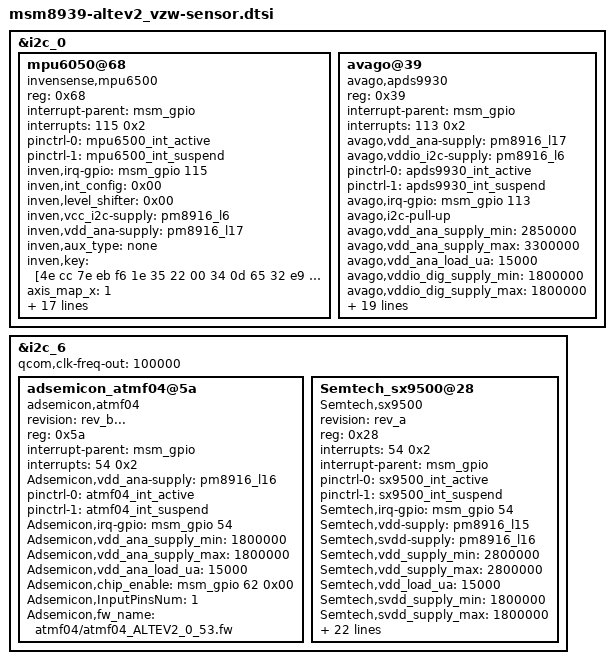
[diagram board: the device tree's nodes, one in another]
/* Copyright (c) 2012, Code Aurora Forum. All rights reserved.
 *
 * This program is free software; you can redistribute it and/or modify
 * it under the terms of the GNU General Public License version 2 and
 * only version 2 as published by the Free Software Foundation.
 *
 * This program is distributed in the hope that it will be useful,
 * but WITHOUT ANY WARRANTY; without even the implied warranty of
 * MERCHANTABILITY or FITNESS FOR A PARTICULAR PURPOSE.  See the
 * GNU General Public License for more details.
 */

&i2c_0{
	/* BLSP1 QUP2, LGP-s19 sensor devices */
	/* LGE_CHANGE_S
	* Comment : add to enable Invensense MPU6515 6-axis sensor
	* 2014-08-05, chaesun.leem@lge.com
	*/
	mpu6050@68{
		compatible = "invensense,mpu6500";
		status = "ok";
		reg = <0x68>;
		interrupt-parent = <&msm_gpio>;
		interrupts = <115 0x2>;
		pinctrl-names = "default", "sleep";
		pinctrl-0 = <&mpu6500_int_active>;
		pinctrl-1 = <&mpu6500_int_suspend>;
		inven,irq-gpio = <&msm_gpio 115 0x00>;		/*	SMS_GPIO_BASE(112) + 3	*/
		inven,int_config = <0x00>;
		inven,level_shifter = <0x00>;
		inven,vcc_i2c-supply = <&pm8916_l6>;
		inven,vdd_ana-supply = <&pm8916_l17>;
		/* inven,secondary_type = "none"; */
		inven,aux_type = "none";
		inven,key = [4e cc 7e eb f6 1e 35 22 00 34 0d 65 32 e9 94 89];
		axis_map_x = <1>;
		axis_map_y = <0>;
		axis_map_z = <2>;
		negate_x = <1>;
		negate_y = <1>;
		negate_z = <1>;

		poll_interval = <200>;
		min_interval = <5>;
		inven,secondary_reg = <0x0c>;
		inven,secondary_reest = <&msm_gpio 69 0x00>;
		/* If no compass sensor,
		 * replace "compass" with "none"
		 */
		inven,secondary_type = "compass";
		inven,secondary_name = "ak09911";
		inven,secondary_axis_map_x = <1>;
		inven,secondary_axis_map_y = <0>;
		inven,secondary_axis_map_z = <2>;
		inven,secondary_negate_x = <1>;
		inven,secondary_negate_y = <1>;
		inven,secondary_negate_z = <1>;
	};
	avago@39{
		compatible = "avago,apds9930";
		status ="ok";
		reg = <0x39>;
		interrupt-parent = <&msm_gpio>;
		interrupts = <113 0x2>;
		avago,vdd_ana-supply = <&pm8916_l17>;
		avago,vddio_i2c-supply = <&pm8916_l6>;
		pinctrl-names = "default", "sleep";
		pinctrl-0 = <&apds9930_int_active>;
		pinctrl-1 = <&apds9930_int_suspend>;
		avago,irq-gpio = <&msm_gpio 113 0x0>;
		avago,i2c-pull-up;
		avago,vdd_ana_supply_min = <2850000>;
		avago,vdd_ana_supply_max = <3300000>;
		avago,vdd_ana_load_ua = <15000>;
		avago,vddio_dig_supply_min = <1800000>;
		avago,vddio_dig_supply_max = <1800000>;
		avago,vddio_dig_load_ua = <10000>;
		avago,vddio_i2c_supply_min = <1800000>;
		avago,vddio_i2c_supply_max = <1800000>;
		avago,vddio_i2c_load_ua = <10000>;
		avago,ppcount = <8>;
		avago,pdrive = <0>;
		avago,near_offset = <300>;
		avago,far_offset = <100>;
		avago,crosstalk_max = <720>;
		avago,bright_threshold = <2000>;
		avago,dark_threshold = <1000>;
		avago,ps_threshold = <250>;
		avago,ps_hysteresis_threshold = <150>;
		avago,ps_pulse = <6>;
		avago,ps_pgain = <0x08>;
		avago,als_B = <186>;
		avago,als_C = <75>;
		avago,als_D = <132>;
		avago,ga_value = <238>;
	};
/*	akm@c{
		compatible = "ak,ak09911";
		status = "ok";
		reg = <0x0c>;
		interrupt-parent = <&msm_gpio>;
		interrupts = <69 0x2>;
		vdd-supply = <&pm8916_l17>;
		vio-supply = <&pm8916_l6>;
		sensor_vdd-supply = <&pm8916_l17>;
		sensor_vcc_i2c-supply = <&pm8916_l6>;
		pinctrl-names = "default", "sleep";
		pinctrl-0 = <&akm09911_active>;
		pinctrl-1 = <&akm09911_suspend>;
		akm,gpio_rstn = <&msm_gpio 69 0x0>;
		akm,layout = <0x0>;
		akm,auto-report;
		};*/
};
&i2c_6{
	qcom,clk-freq-out = <100000>;
	adsemicon_atmf04@5a {
		compatible = "adsemicon,atmf04";
		status = "ok";
		revision = "rev_b...";
		reg = <0x5a>;
		interrupt-parent = <&msm_gpio>;
		interrupts = <54 0x2>;
		Adsemicon,vdd_ana-supply = <&pm8916_l16>;
		pinctrl-names = "default", "sleep";
		pinctrl-0 = <&atmf04_int_active>;
		pinctrl-1 = <&atmf04_int_suspend>;
		Adsemicon,irq-gpio = <&msm_gpio 54 0x00>;
		Adsemicon,vdd_ana_supply_min = <1800000>;
		Adsemicon,vdd_ana_supply_max = <1800000>;
		Adsemicon,vdd_ana_load_ua = <15000>;
		Adsemicon,chip_enable = <&msm_gpio 62 0x00>;
		Adsemicon,InputPinsNum = <1>;
		Adsemicon,fw_name = "atmf04/atmf04_ALTEV2_0_53.fw";
	};
	/* sx9500 cap sensor */
	Semtech_sx9500@28 {
		compatible = "Semtech,sx9500";
		status = "ok";
		revision = "rev_a";
		reg = <0x28>;
		interrupts = <54 0x2>;
		interrupt-parent = <&msm_gpio>;
		pinctrl-names = "default", "sleep";
		pinctrl-0 = <&sx9500_int_active>;
		pinctrl-1 = <&sx9500_int_suspend>;
		Semtech,irq-gpio = <&msm_gpio 54 0x00>;
		Semtech,vdd-supply = <&pm8916_l15>;
		Semtech,svdd-supply = <&pm8916_l16>;
		Semtech,vdd_supply_min = <2800000>;
		Semtech,vdd_supply_max = <2800000>;
		Semtech,vdd_load_ua = <15000>;
		Semtech,svdd_supply_min = <1800000>;
		Semtech,svdd_supply_max = <1800000>;
		Semtech,svdd_load_ua = <10000>;
		Semtech,RegIrqMask = <0x03 0x70>;
		Semtech,RegProxCtrl0 = <0x06 0x5C>;
		Semtech,RegProxCtrl1 = <0x07 0x02>;
		Semtech,RegProxCtrl2 = <0x08 0x77>;
		Semtech,RegProxCtrl3 = <0x09 0x01>;
		Semtech,RegProxCtrl4 = <0x0A 0x40>;
		Semtech,RegProxCtrl5 = <0x0B 0x0D>;
		Semtech,RegProxCtrl6 = <0x0C 0x09>;
		Semtech,RegProxCtrl7 = <0x0D 0x00>;
		Semtech,RegProxCtrl8 = <0x0E 0x00>;
		Semtech,RegSensorSel = <0x20 0x02>;
		Semtech,InputPinsNum = <1>;
		Semtech,InputMainSensor = <0x02>;
		Semtech,InputMainSensor2 = <0x0F>;
		Semtech,InputRefSensor = <0x03>;
		Semtech,DynamicThres_Offset = <43000>;
		Semtech,DynamicThres_Temp_Slope = <40>;
		Semtech,DynamicThres_Hysteresis = <600>;
		Semtech,Calibration_Margin = <0>;
		Semtech,Startup_Touch_RegAvgThres = <0x29>;
		Semtech,Startup_Release_RegAvgThres = <0x40>;
	};
};
